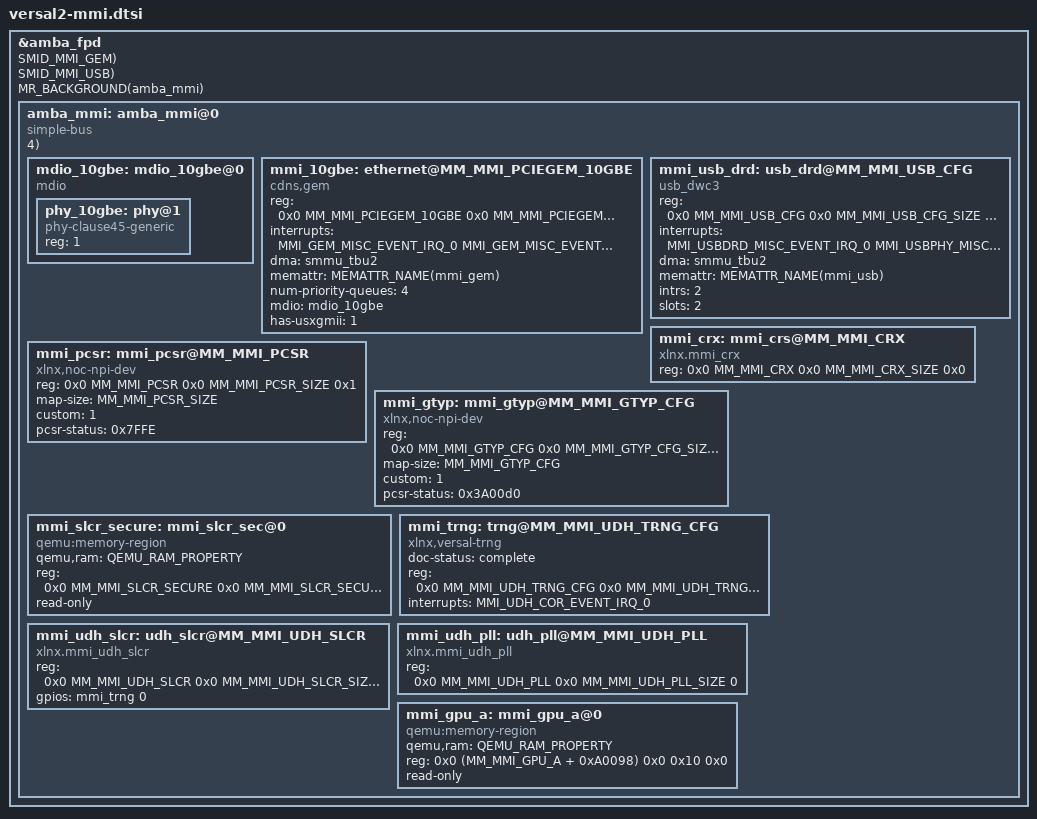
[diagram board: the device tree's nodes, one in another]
/*
 * Versal Gen 2 MMI
 *
 * Copyright (C) 2023, Advanced Micro Devices, Inc.
 * All rights reserved.
 *
 * Redistribution and use in source and binary forms, with or without
 * modification, are permitted provided that the following conditions are met:
 *     * Redistributions of source code must retain the above copyright
 *       notice, this list of conditions and the following disclaimer.
 *     * Redistributions in binary form must reproduce the above copyright
 *       notice, this list of conditions and the following disclaimer in the
 *       documentation and/or other materials provided with the distribution.
 *     * Neither the name of the <organization> nor the
 *       names of its contributors may be used to endorse or promote products
 *       derived from this software without specific prior written permission.
 *
 * THIS SOFTWARE IS PROVIDED BY THE COPYRIGHT HOLDERS AND CONTRIBUTORS "AS IS" AND
 * ANY EXPRESS OR IMPLIED WARRANTIES, INCLUDING, BUT NOT LIMITED TO, THE IMPLIED
 * WARRANTIES OF MERCHANTABILITY AND FITNESS FOR A PARTICULAR PURPOSE ARE
 * DISCLAIMED. IN NO EVENT SHALL <COPYRIGHT HOLDER> BE LIABLE FOR ANY
 * DIRECT, INDIRECT, INCIDENTAL, SPECIAL, EXEMPLARY, OR CONSEQUENTIAL DAMAGES
 * (INCLUDING, BUT NOT LIMITED TO, PROCUREMENT OF SUBSTITUTE GOODS OR SERVICES;
 * LOSS OF USE, DATA, OR PROFITS; OR BUSINESS INTERRUPTION) HOWEVER CAUSED AND
 * ON ANY THEORY OF LIABILITY, WHETHER IN CONTRACT, STRICT LIABILITY, OR TORT
 * (INCLUDING NEGLIGENCE OR OTHERWISE) ARISING IN ANY WAY OUT OF THE USE OF THIS
 * SOFTWARE, EVEN IF ADVISED OF THE POSSIBILITY OF SUCH DAMAGE.
 */

&amba_fpd {
	MEMATTR(mmi_gem, NON_SECURE, SMID_MMI_GEM);
	MEMATTR(mmi_usb, NON_SECURE, SMID_MMI_USB);

	amba_mmi: amba_mmi@0 {
		#address-cells = <2>;
		#size-cells = <2>;
		#priority-cells = <1>;
		compatible = "simple-bus";
		ranges;
		mdio_10gbe: mdio_10gbe@0 {
			#address-cells = <1>;
			#size-cells = <0>;
			#priority-cells = <0>;
			compatible="mdio";
			phy_10gbe: phy@1 {
				compatible = "phy-clause45-generic";
				device_type = "ethernet-phy";
				reg = <1>;
			};
		};

		mmi_10gbe: ethernet@MM_MMI_PCIEGEM_10GBE {
			#address-cells = <1>;
			#size-cells = <0>;
			#priority-cells = <0>;
			compatible = "cdns,gem";
			reg = <0x0 MM_MMI_PCIEGEM_10GBE 0x0 MM_MMI_PCIEGEM_10GBE_SIZE 0x0>;
			interrupts = <MMI_GEM_MISC_EVENT_IRQ_0
				MMI_GEM_MISC_EVENT_IRQ_0
				MMI_GEM_MISC_EVENT_IRQ_0
				MMI_GEM_MISC_EVENT_IRQ_0>;
			dma = <&smmu_tbu2>;
			memattr = <&MEMATTR_NAME(mmi_gem)>;
			num-priority-queues = <4>;
			mdio = <&mdio_10gbe>;
			has-usxgmii = <1>;
		};

		mmi_usb_drd: usb_drd@MM_MMI_USB_CFG {
			compatible = "usb_dwc3";
			reg = <0x0 MM_MMI_USB_CFG 0x0 MM_MMI_USB_CFG_SIZE 0x0>;
			interrupts = <MMI_USBDRD_MISC_EVENT_IRQ_0
				MMI_USBPHY_MISC_EVENT_IRQ_0>;
			dma = <&smmu_tbu2>;
			memattr = <&MEMATTR_NAME(mmi_usb)>;
			intrs = <2>;
			slots = <2>;
		};

		mmi_crx: mmi_crs@MM_MMI_CRX {
			compatible = "xlnx.mmi_crx";
			reg = <0x0 MM_MMI_CRX 0x0 MM_MMI_CRX_SIZE 0x0>;
		};

		mmi_pcsr: mmi_pcsr@MM_MMI_PCSR {
			compatible = "xlnx,noc-npi-dev";
			reg = <0x0 MM_MMI_PCSR 0x0 MM_MMI_PCSR_SIZE 0x1>;
			map-size = <MM_MMI_PCSR_SIZE>;
			custom = <1>;
			pcsr-status = <0x7FFE>;
		};

		mmi_gtyp: mmi_gtyp@MM_MMI_GTYP_CFG {
			compatible = "xlnx,noc-npi-dev";
			reg = <0x0 MM_MMI_GTYP_CFG 0x0 MM_MMI_GTYP_CFG_SIZE 0x1>;
			map-size = <MM_MMI_GTYP_CFG>;
			custom = <1>;
			pcsr-status = <0x3A00d0>;
		};

		mmi_slcr_secure: mmi_slcr_sec@0 {
			compatible = "qemu:memory-region";
			qemu,ram = <QEMU_RAM_PROPERTY>;
			reg = <0x0 MM_MMI_SLCR_SECURE 0x0 MM_MMI_SLCR_SECURE_SIZE 0x0>;
			read-only;
		};

		mmi_trng: trng@MM_MMI_UDH_TRNG_CFG {
			doc-status = "complete";
			compatible = "xlnx,versal-trng";
			reg = <0x0 MM_MMI_UDH_TRNG_CFG 0x0 MM_MMI_UDH_TRNG_CFG_SIZE 0x0>;
			interrupts = <MMI_UDH_COR_EVENT_IRQ_0>;
			#gpio-cells = <1>;
		};

		mmi_udh_slcr: udh_slcr@MM_MMI_UDH_SLCR {
			compatible = "xlnx.mmi_udh_slcr";
			reg = <0x0 MM_MMI_UDH_SLCR 0x0 MM_MMI_UDH_SLCR_SIZE 0>;
			gpios = <&mmi_trng 0>;
		};

		mmi_udh_pll: udh_pll@MM_MMI_UDH_PLL {
			compatible = "xlnx.mmi_udh_pll";
			reg = <0x0 MM_MMI_UDH_PLL 0x0 MM_MMI_UDH_PLL_SIZE 0>;
		};

		mmi_gpu_a: mmi_gpu_a@0 {
			compatible = "qemu:memory-region";
			qemu,ram = <QEMU_RAM_PROPERTY>;
			reg = <0x0 (MM_MMI_GPU_A + 0xA0098) 0x0 0x10 0x0>;
			read-only;
		};

		LOADER_DEBUG_WRITE(0, 0xEDC30440, 0x1, 4);
		LOADER_DEBUG_WRITE(0, 0xEDC30444, 0x7F, 4);
		LOADER_DEBUG_WRITE(0, 0xEDC3044c, 0x1, 4);
		LOADER_DEBUG_WRITE(0, 0xEDC30450, 0x1, 4);
		LOADER_DEBUG_WRITE(0, 0xEDC30460, 0x1, 4);
		LOADER_DEBUG_WRITE(0, 0xEDC30464, 0x7f, 4);
		LOADER_DEBUG_WRITE(0, 0xEDC3046c, 0x1, 4);
		LOADER_DEBUG_WRITE(0, 0xEDC30470, 0x1, 4);
		LOADER_DEBUG_WRITE(0, 0xED0A0098, 0x3, 4);
	};

	MR_BACKGROUND(amba_mmi);
};
